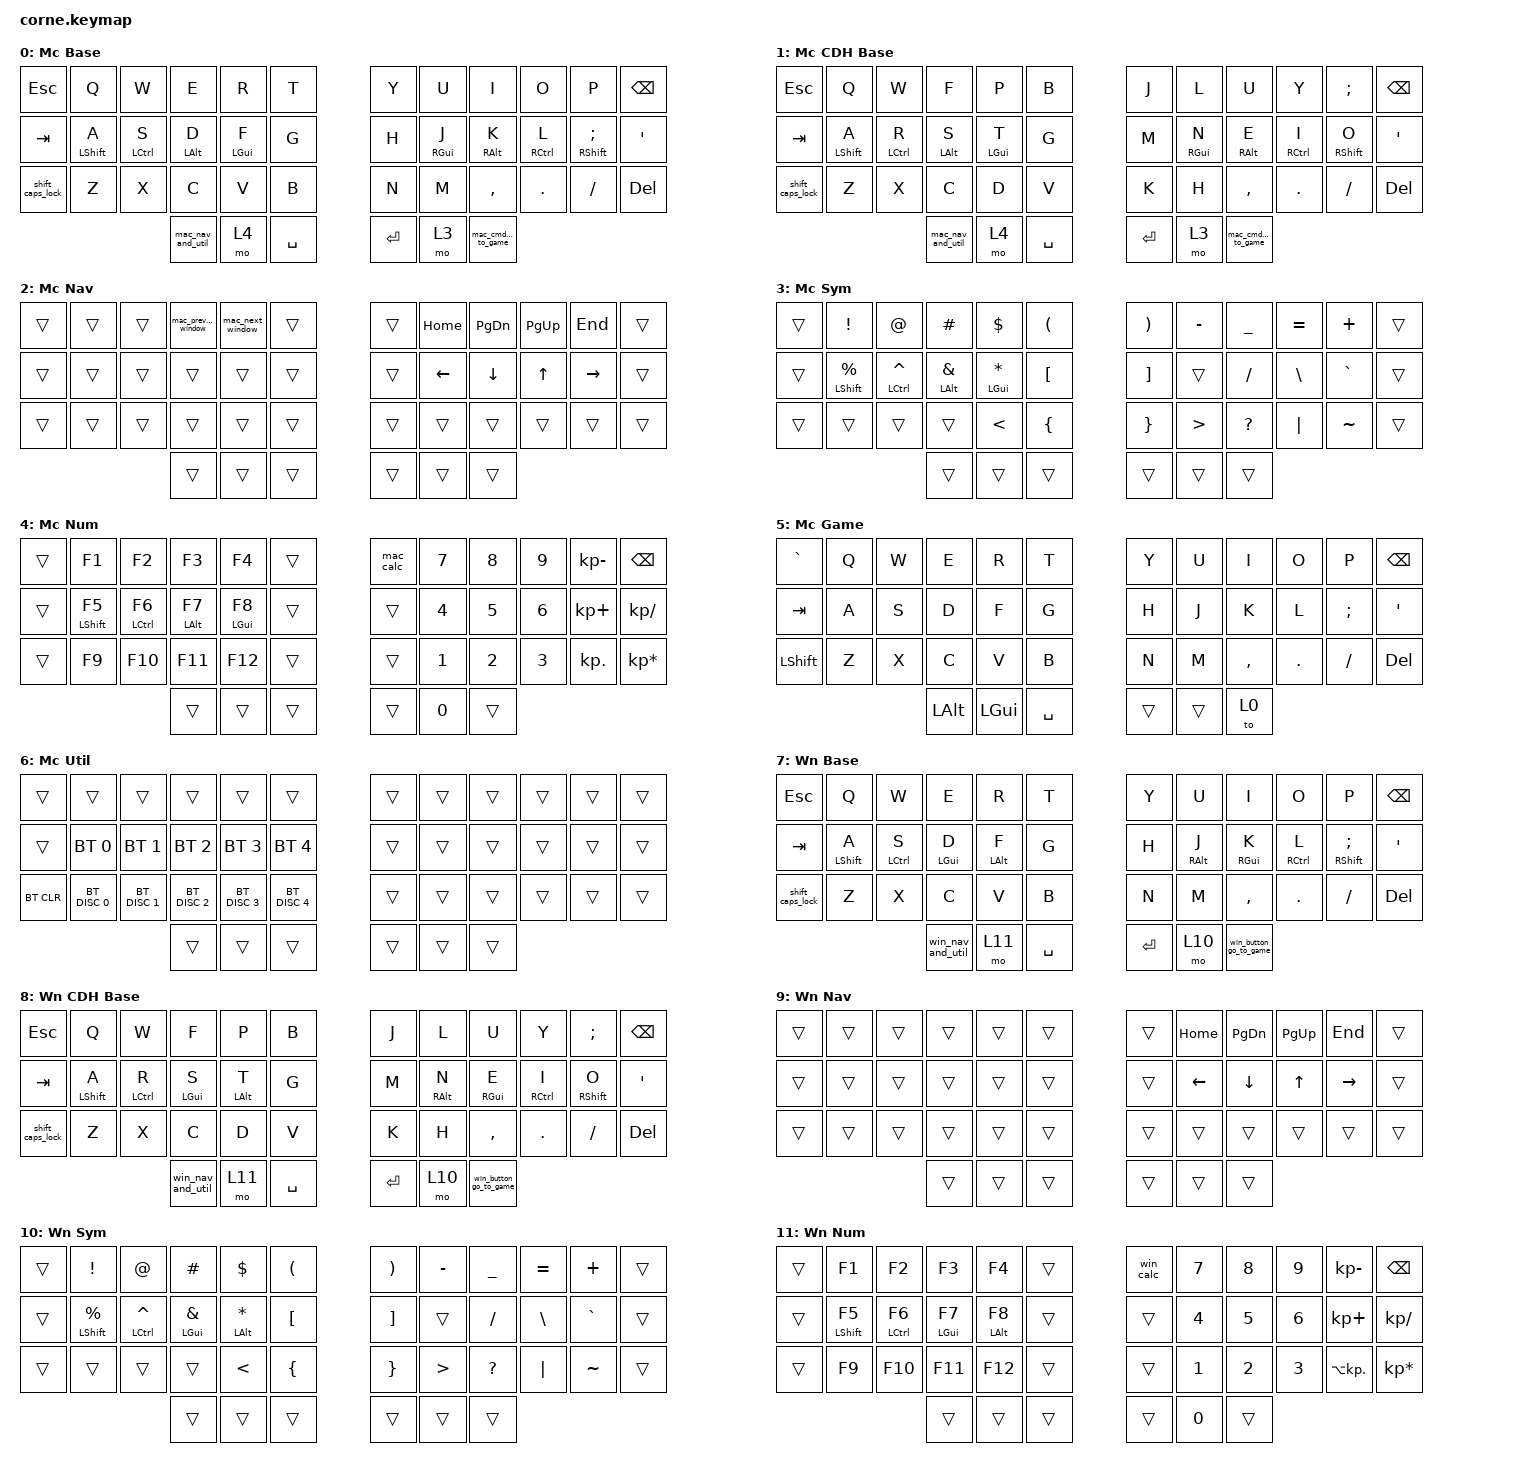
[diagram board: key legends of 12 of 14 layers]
/*
 * Copyright (c) 2020 The ZMK Contributors
 *
 * SPDX-License-Identifier: MIT
 */

#include <behaviors.dtsi>
#include <dt-bindings/zmk/bt.h>
#include <dt-bindings/zmk/keys.h>
#include <dt-bindings/zmk/keys.h>

&mt { flavor = "balanced"; };

/ {
    combos {
        compatible = "zmk,combos";

        to_win_base_qwerty {
            bindings = <&to 7>;
            key-positions = <11 23 35>;
            layers = <0>;
            require-prior-idle-ms = <500>;
        };

        to_mac_base_qwerty {
            bindings = <&to 0>;
            key-positions = <11 23 35>;
            layers = <7>;
            require-prior-idle-ms = <500>;
        };

        win_game_escape {
            bindings = <&kp ESCAPE>;
            key-positions = <0 37>;
            require-prior-idle-ms = <500>;
            layers = <12 5>;
        };

        switch_to_mac_colemak_dh {
            bindings = <&to 1>;
            key-positions = <0 12 24>;
            layers = <0>;
        };

        switch_to_mac_qwerty {
            bindings = <&to 0>;
            key-positions = <0 12 24>;
            layers = <1>;
        };

        switch_to_win_colemak_dh {
            bindings = <&to 8>;
            key-positions = <0 12 24>;
            layers = <7>;
        };

        switch_to_win_qwerty {
            bindings = <&to 7>;
            key-positions = <0 12 24>;
            layers = <8>;
        };

        to_mac_colemak_dh {
            bindings = <&to 1>;
            key-positions = <11 23 35>;
            layers = <8>;
        };

        to_win_colemak_dh {
            bindings = <&to 8>;
            key-positions = <11 23 35>;
            layers = <1>;
        };
    };

    macros {
        win_calc: calc {
            compatible = "zmk,behavior-macro";
            #binding-cells = <0>;
            bindings = <&kp LGUI &kp C &kp A &kp L &kp C &kp RETURN>;
            label = "CALC";
        };

        mac_calc: maccalc {
            compatible = "zmk,behavior-macro";
            #binding-cells = <0>;
            bindings = <&kt LGUI &kp SPACE &kt LGUI &kp C &kp A &kp L &kp C &kp RETURN>;
            label = "MACCALC";
        };

        mac_next_window: mac_next_window {
            compatible = "zmk,behavior-macro";
            #binding-cells = <0>;
            bindings = <&kt LGUI &kp GRAVE &kt LGUI>;
            label = "MAC_NEXT_WINDOW";
        };

        mac_previous_window: mac_previous_window {
            compatible = "zmk,behavior-macro";
            #binding-cells = <0>;
            bindings = <&kt LGUI &kt LEFT_SHIFT &kp GRAVE &kt LGUI &kt LEFT_SHIFT>;
            label = "MAC_PREVIOUS_WINDOW";
        };
    };

    behaviors {
        win_button_go_to_game: win_button_go_to_game {
            compatible = "zmk,behavior-tap-dance";
            label = "WIN_BUTTON_GO_TO_GAME";
            #binding-cells = <0>;
            bindings = <&kp LGUI>, <&none>, <&to 12>;
        };

        mac_cmd_go_to_game: mac_cmd_go_to_game {
            compatible = "zmk,behavior-tap-dance";
            label = "MAC_CMD_GO_TO_GAME";
            #binding-cells = <0>;
            bindings = <&kp LGUI>, <&none>, <&to 5>;
        };

        shift_caps_lock: shift_caps_lock {
            compatible = "zmk,behavior-tap-dance";
            label = "SHIFT_CAPS_LOCK";
            #binding-cells = <0>;
            bindings = <&kp LEFT_SHIFT>, <&kt CAPSLOCK>;
        };

        mac_nav_and_util: mac_nav_and_util {
            compatible = "zmk,behavior-tap-dance";
            label = "MAC_NAV_AND_UTIL";
            #binding-cells = <0>;
            bindings = <&mo 2>, <&none>, <&mo 6>;
        };

        win_nav_and_util: win_nav_and_util {
            compatible = "zmk,behavior-tap-dance";
            label = "WIN_NAV_AND_UTIL";
            #binding-cells = <0>;
            bindings = <&mo 9>, <&none>, <&mo 13>;
        };
    };

    keymap {
        compatible = "zmk,keymap";

        mac_base {
            label = "Mc Base";
            bindings = <
&kp ESC           &kp Q             &kp W               &kp E              &kp R           &kp T        &kp Y       &kp U            &kp I                &kp O                &kp P                      &kp BSPC
&kp TAB           &mt LEFT_SHIFT A  &mt LEFT_CONTROL S  &mt LEFT_ALT D     &mt LEFT_GUI F  &kp G        &kp H       &mt RIGHT_GUI J  &mt RIGHT_ALT K      &mt RIGHT_CONTROL L  &mt RIGHT_SHIFT SEMICOLON  &kp SQT
&shift_caps_lock  &kp Z             &kp X               &kp C              &kp V           &kp B        &kp N       &kp M            &kp COMMA            &kp DOT              &kp FSLH                   &kp DELETE
                                                        &mac_nav_and_util  &mo 4           &kp SPACE    &kp RETURN  &mo 3            &mac_cmd_go_to_game
            >;
        };

        mac_base_colemak_dh {
            // -----------------------------------------------------------------------------------------
            // |  TAB |  Q  |  W  |  E  |  R  |  T  |   |  Y  |  U   |  I  |  O  |  P  | BKSP |
            // | CTRL |  A  |  S  |  D  |  F  |  G  |   |  H  |  J   |  K  |  L  |  ;  |  '   |
            // | SHFT |  Z  |  X  |  C  |  V  |  B  |   |  N  |  M   |  ,  |  .  |  /  | ESC  |
            //                    | GUI | LWR | SPC |   | ENT | RSE  | ALT |

            bindings = <
&kp ESC           &kp Q             &kp W               &kp F              &kp P           &kp B        &kp J    &kp L            &kp U                &kp Y                &kp SEMICOLON      &kp BSPC
&kp TAB           &mt LEFT_SHIFT A  &mt LEFT_CONTROL R  &mt LEFT_ALT S     &mt LEFT_GUI T  &kp G        &kp M    &mt RIGHT_GUI N  &mt RIGHT_ALT E      &mt RIGHT_CONTROL I  &mt RIGHT_SHIFT O  &kp SQT
&shift_caps_lock  &kp Z             &kp X               &kp C              &kp D           &kp V        &kp K    &kp H            &kp COMMA            &kp DOT              &kp FSLH           &kp DELETE
                                                        &mac_nav_and_util  &mo 4           &kp SPACE    &kp RET  &mo 3            &mac_cmd_go_to_game
            >;

            label = "Mc CDH Base";
        };

        mac_nav {
            // -----------------------------------------------------------------------------------------
            // |  TAB |  1  |  2  |  3  |  4  |  5  |   |  6  |  7  |  8  |  9  |  0  | BKSP |
            // | BTCLR| BT1 | BT2 | BT3 | BT4 | BT5 |   | LFT | DWN |  UP | RGT |     |      |
            // | SHFT |     |     |     |     |     |   |     |     |     |     |     |      |
            //                    | GUI |     | SPC |   | ENT |     | ALT |

            bindings = <
&trans  &trans  &trans  &mac_previous_window  &mac_next_window  &trans    &trans  &kp HOME  &kp PAGE_DOWN  &kp PAGE_UP   &kp END    &trans
&trans  &trans  &trans  &trans                &trans            &trans    &trans  &kp LEFT  &kp DOWN       &kp UP_ARROW  &kp RIGHT  &trans
&trans  &trans  &trans  &trans                &trans            &trans    &trans  &trans    &trans         &trans        &trans     &trans
                        &trans                &trans            &trans    &trans  &trans    &trans
            >;

            label = "Mc Nav";
        };

        mac_sym {
            // -----------------------------------------------------------------------------------------
            // |  TAB |  !  |  @  |  #  |  $  |  %  |   |  ^  |  &  |  *  |  (  |  )  | BKSP |
            // | CTRL |     |     |     |     |     |   |  -  |  =  |  [  |  ]  |  \  |  `   |
            // | SHFT |     |     |     |     |     |   |  _  |  +  |  {  |  }  | "|" |  ~   |
            //                    | GUI |     | SPC |   | ENT |     | ALT |

            bindings = <
&trans  &kp EXCL                &kp AT                  &kp HASH           &kp DLLR            &kp LEFT_PARENTHESIS    &kp RIGHT_PARENTHESIS  &kp MINUS         &kp UNDER     &kp EQUAL      &kp PLUS   &trans
&trans  &mt LEFT_SHIFT PERCENT  &mt LEFT_CONTROL CARET  &mt LEFT_ALT AMPS  &mt LEFT_GUI ASTRK  &kp LEFT_BRACKET        &kp RIGHT_BRACKET      &trans            &kp SLASH     &kp BACKSLASH  &kp GRAVE  &trans
&trans  &trans                  &trans                  &trans             &kp LESS_THAN       &kp LBRC                &kp RBRC               &kp GREATER_THAN  &kp QUESTION  &kp PIPE       &kp TILDE  &trans
                                                        &trans             &trans              &trans                  &trans                 &trans            &trans
            >;

            label = "Mc Sym";
        };

        mac_num {
            bindings = <
&trans  &kp F1             &kp F2               &kp F3           &kp F4           &trans    &mac_calc  &kp NUMBER_7  &kp NUMBER_8  &kp NUMBER_9  &kp KP_SUBTRACT  &kp BSPC
&trans  &mt LEFT_SHIFT F5  &mt LEFT_CONTROL F6  &mt LEFT_ALT F7  &mt LEFT_GUI F8  &trans    &trans     &kp NUMBER_4  &kp NUMBER_5  &kp NUMBER_6  &kp KP_PLUS      &kp KP_DIVIDE
&trans  &kp F9             &kp F10              &kp F11          &kp F12          &trans    &trans     &kp NUMBER_1  &kp NUMBER_2  &kp NUMBER_3  &kp KP_DOT       &kp KP_MULTIPLY
                                                &trans           &trans           &trans    &trans     &kp NUMBER_0  &trans
            >;

            label = "Mc Num";
        };

        mac_game {
            bindings = <
&kp GRAVE  &kp Q  &kp W  &kp E     &kp R     &kp T        &kp Y   &kp U   &kp I      &kp O    &kp P     &kp BSPC
&kp TAB    &kp A  &kp S  &kp D     &kp F     &kp G        &kp H   &kp J   &kp K      &kp L    &kp SEMI  &kp APOS
&kp LSHFT  &kp Z  &kp X  &kp C     &kp V     &kp B        &kp N   &kp M   &kp COMMA  &kp DOT  &kp FSLH  &kp DEL
                         &kp LALT  &kp LGUI  &kp SPACE    &trans  &trans  &to 0
            >;

            label = "Mc Game";
        };

        mac_util {
            label = "Mc Util";
            bindings = <
&trans      &trans         &trans         &trans         &trans         &trans           &trans  &trans  &trans  &trans  &trans  &trans
&trans      &bt BT_SEL 0   &bt BT_SEL 1   &bt BT_SEL 2   &bt BT_SEL 3   &bt BT_SEL 4     &trans  &trans  &trans  &trans  &trans  &trans
&bt BT_CLR  &bt BT_DISC 0  &bt BT_DISC 1  &bt BT_DISC 2  &bt BT_DISC 3  &bt BT_DISC 4    &trans  &trans  &trans  &trans  &trans  &trans
                                          &trans         &trans         &trans           &trans  &trans  &trans
            >;
        };

        win_base {
            bindings = <
&kp ESC           &kp Q             &kp W               &kp E              &kp R           &kp T        &kp Y       &kp U            &kp I                   &kp O                &kp P                      &kp BSPC
&kp TAB           &mt LEFT_SHIFT A  &mt LEFT_CONTROL S  &mt LEFT_GUI D     &mt LEFT_ALT F  &kp G        &kp H       &mt RIGHT_ALT J  &mt RIGHT_GUI K         &mt RIGHT_CONTROL L  &mt RIGHT_SHIFT SEMICOLON  &kp SQT
&shift_caps_lock  &kp Z             &kp X               &kp C              &kp V           &kp B        &kp N       &kp M            &kp COMMA               &kp DOT              &kp FSLH                   &kp DELETE
                                                        &win_nav_and_util  &mo 11          &kp SPACE    &kp RETURN  &mo 10           &win_button_go_to_game
            >;

            label = "Wn Base";
        };

        win_base_colemak_dh {
            label = "Wn CDH Base";
            bindings = <
&kp ESC           &kp Q             &kp W               &kp F              &kp P           &kp B        &kp J       &kp L            &kp U                   &kp Y                &kp SEMICOLON      &kp BSPC
&kp TAB           &mt LEFT_SHIFT A  &mt LEFT_CONTROL R  &mt LEFT_GUI S     &mt LEFT_ALT T  &kp G        &kp M       &mt RIGHT_ALT N  &mt RIGHT_GUI E         &mt RIGHT_CONTROL I  &mt RIGHT_SHIFT O  &kp SQT
&shift_caps_lock  &kp Z             &kp X               &kp C              &kp D           &kp V        &kp K       &kp H            &kp COMMA               &kp DOT              &kp FSLH           &kp DELETE
                                                        &win_nav_and_util  &mo 11          &kp SPACE    &kp RETURN  &mo 10           &win_button_go_to_game
            >;
        };

        win_nav {
            label = "Wn Nav";
            bindings = <
&trans  &trans  &trans  &trans  &trans  &trans    &trans  &kp HOME  &kp PAGE_DOWN  &kp PAGE_UP   &kp END    &trans
&trans  &trans  &trans  &trans  &trans  &trans    &trans  &kp LEFT  &kp DOWN       &kp UP_ARROW  &kp RIGHT  &trans
&trans  &trans  &trans  &trans  &trans  &trans    &trans  &trans    &trans         &trans        &trans     &trans
                        &trans  &trans  &trans    &trans  &trans    &trans
            >;
        };

        win_sym {
            label = "Wn Sym";
            bindings = <
&trans  &kp EXCL                &kp AT                  &kp HASH           &kp DLLR            &kp LEFT_PARENTHESIS    &kp RIGHT_PARENTHESIS  &kp MINUS         &kp UNDER     &kp EQUAL      &kp PLUS   &trans
&trans  &mt LEFT_SHIFT PERCENT  &mt LEFT_CONTROL CARET  &mt LEFT_GUI AMPS  &mt LEFT_ALT ASTRK  &kp LEFT_BRACKET        &kp RIGHT_BRACKET      &trans            &kp SLASH     &kp BACKSLASH  &kp GRAVE  &trans
&trans  &trans                  &trans                  &trans             &kp LESS_THAN       &kp LBRC                &kp RBRC               &kp GREATER_THAN  &kp QUESTION  &kp PIPE       &kp TILDE  &trans
                                                        &trans             &trans              &trans                  &trans                 &trans            &trans
            >;
        };

        win_num {
            label = "Wn Num";
            bindings = <
&trans  &kp F1             &kp F2               &kp F3           &kp F4           &trans    &win_calc  &kp NUMBER_7  &kp NUMBER_8  &kp NUMBER_9  &kp KP_SUBTRACT  &kp BSPC
&trans  &mt LEFT_SHIFT F5  &mt LEFT_CONTROL F6  &mt LEFT_GUI F7  &mt LEFT_ALT F8  &trans    &trans     &kp NUMBER_4  &kp NUMBER_5  &kp NUMBER_6  &kp KP_PLUS      &kp KP_DIVIDE
&trans  &kp F9             &kp F10              &kp F11          &kp F12          &trans    &trans     &kp NUMBER_1  &kp NUMBER_2  &kp NUMBER_3  &kp LA(KP_DOT)   &kp KP_MULTIPLY
                                                &trans           &trans           &trans    &trans     &kp NUMBER_0  &trans
            >;
        };

        win_game {
            bindings = <
&kp GRAVE  &kp Q  &kp W  &kp E             &kp R         &kp T        &kp Y   &kp U     &kp I      &kp O    &kp P     &kp BSPC
&kp TAB    &kp A  &kp S  &kp D             &kp F         &kp G        &kp H   &kp J     &kp K      &kp L    &kp SEMI  &kp APOS
&kp LSHFT  &kp Z  &kp X  &kp C             &kp V         &kp B        &kp N   &kp M     &kp COMMA  &kp DOT  &kp FSLH  &kp DEL
                         &kp LEFT_CONTROL  &kp LEFT_ALT  &kp SPACE    &trans  &kp LGUI  &to 7
            >;

            label = "Wn Game";
        };

        win_util {
            label = "Wn Util";
            bindings = <
&trans      &trans         &trans         &trans         &trans         &trans           &trans  &trans  &trans  &trans  &trans  &trans
&trans      &bt BT_SEL 0   &bt BT_SEL 1   &bt BT_SEL 2   &bt BT_SEL 3   &bt BT_SEL 4     &trans  &trans  &trans  &trans  &trans  &trans
&bt BT_CLR  &bt BT_DISC 0  &bt BT_DISC 1  &bt BT_DISC 2  &bt BT_DISC 3  &bt BT_DISC 4    &trans  &trans  &trans  &trans  &trans  &trans
                                          &trans         &trans         &trans           &trans  &trans  &trans
            >;
        };
    };
};
